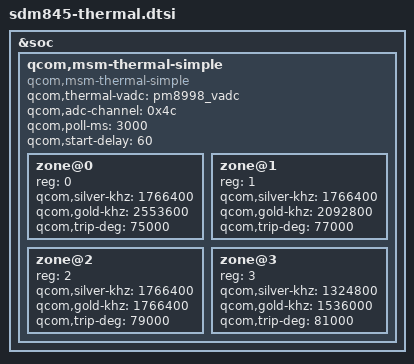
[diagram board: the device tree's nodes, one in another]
/* Copyright (c) 2016-2019, The Linux Foundation. All rights reserved.
 *
 * This program is free software; you can redistribute it and/or modify
 * it under the terms of the GNU General Public License version 2 and
 * only version 2 as published by the Free Software Foundation.
 *
 * This program is distributed in the hope that it will be useful,
 * but WITHOUT ANY WARRANTY; without even the implied warranty of
 * MERCHANTABILITY or FITNESS FOR A PARTICULAR PURPOSE.  See the
 * GNU General Public License for more details.
 */

&soc {
	qcom,msm-thermal-simple {
		#address-cells = <1>;
		#size-cells = <0>;
		compatible = "qcom,msm-thermal-simple";
		qcom,thermal-vadc = <&pm8998_vadc>;
		qcom,adc-channel = <0x4c>;
		qcom,poll-ms = <3000>;
		qcom,start-delay = <60>;
		zone@0 {
			reg = <0>;
			qcom,silver-khz = <1766400>;
			qcom,gold-khz = <2553600>;
			qcom,trip-deg = <75000>;
		};

		zone@1 {
			reg = <1>;
			qcom,silver-khz = <1766400>;
			qcom,gold-khz = <2092800>;
			qcom,trip-deg = <77000>;
		};

		zone@2 {
			reg = <2>;
			qcom,silver-khz = <1766400>;
			qcom,gold-khz = <1766400>;
			qcom,trip-deg = <79000>;
		};

		zone@3 {
			reg = <3>;
			qcom,silver-khz = <1324800>;
			qcom,gold-khz = <1536000>;
			qcom,trip-deg = <81000>;
		};
	};
};
